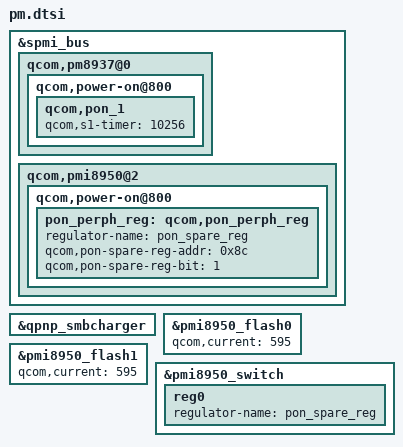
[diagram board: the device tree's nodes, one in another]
/* FROM: msm-pm8937.dtsi */
&spmi_bus {
	qcom,pm8937@0 {
		qcom,power-on@800 {
			qcom,pon_1 {
				qcom,s1-timer = <10256>;
			};
		};
	};
};

/* FROM: msm-pmi8950.dtsi */
&spmi_bus {
	qcom,pmi8950@2 {
		qcom,power-on@800 {
			pon_perph_reg: qcom,pon_perph_reg {
				regulator-name = "pon_spare_reg";
				qcom,pon-spare-reg-addr = <0x8c>;
				qcom,pon-spare-reg-bit = <1>;
			};
		};
	};
};

&qpnp_smbcharger {
	/delete-property/ qcom,parallel-usb-min-current-ma;
	/delete-property/ qcom,parallel-usb-9v-min-current-ma;
	/delete-property/ qcom,parallel-allowed-lowering-ma;
};

&pmi8950_flash0 {
	qcom,current = <595>;
};

&pmi8950_flash1 {
	qcom,current = <595>;
};

&pmi8950_switch {
	reg0 {
		regulator-name = "pon_spare_reg";
	};
};
